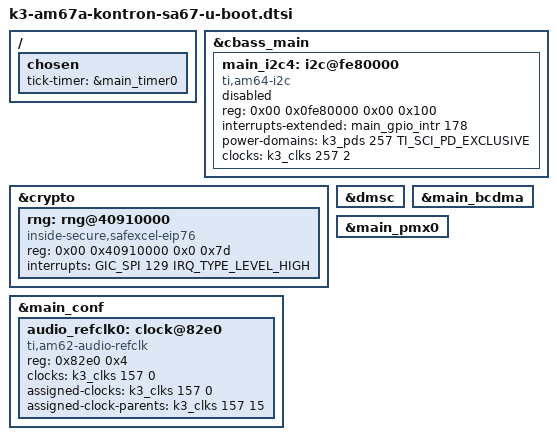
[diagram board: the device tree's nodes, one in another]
// SPDX-License-Identifier: GPL-2.0
/*
 * Copyright (c) 2025 Kontron Europe GmbH
 */

#include "k3-am67a-kontron-sa67-binman.dtsi"

/ {
	chosen {
		tick-timer = &main_timer0;
	};
};

/* can be removed when upstream soc dtsi is updated */
&cbass_main {
	main_i2c4: i2c@fe80000 {
		compatible = "ti,am64-i2c", "ti,omap4-i2c";
		reg = <0x00 0x0fe80000 0x00 0x100>;
		interrupts-extended = <&main_gpio_intr 178>;
		#address-cells = <1>;
		#size-cells = <0>;
		power-domains = <&k3_pds 257 TI_SCI_PD_EXCLUSIVE>;
		clocks = <&k3_clks 257 2>;
		clock-names = "fck";
		status = "disabled";
	};
};

&crypto {
	rng: rng@40910000 {
		compatible = "inside-secure,safexcel-eip76";
		reg = <0x00 0x40910000 0x0 0x7d>;
		interrupts = <GIC_SPI 129 IRQ_TYPE_LEVEL_HIGH>;
	};
};

&dmsc {
	bootph-pre-ram;
};

&main_bcdma {
	bootph-pre-ram;
};

/* can be removed when upstream soc dtsi is updated */
&main_conf {
	audio_refclk0: clock@82e0 {
		compatible = "ti,am62-audio-refclk";
		reg = <0x82e0 0x4>;
		clocks = <&k3_clks 157 0>;
		assigned-clocks = <&k3_clks 157 0>;
		assigned-clock-parents = <&k3_clks 157 15>;
		#clock-cells = <0>;
	};
};

/* can be removed when upstream soc dtsi is updated */
&main_pmx0 {
	/delete-property/ pinctrl-single,gpio-range;
	/delete-node/ gpio-range;
};
